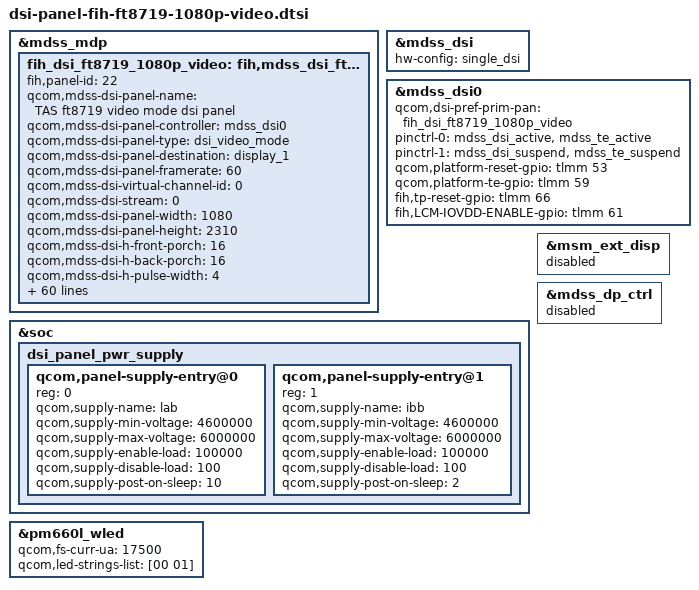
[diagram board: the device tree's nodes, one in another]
/* Copyright (c) 2013, The Linux Foundation. All rights reserved.
 *
 * This program is free software; you can redistribute it and/or modify
 * it under the terms of the GNU General Public License version 2 and
 * only version 2 as published by the Free Software Foundation.
 *
 * This program is distributed in the hope that it will be useful,
 * but WITHOUT ANY WARRANTY; without even the implied warranty of
 * MERCHANTABILITY or FITNESS FOR A PARTICULAR PURPOSE.  See the
 * GNU General Public License for more details.
 */

/*---------------------------------------------------------------------------
 * This file is autogenerated file using gcdb parser. Please do not edit it.
 * Update input XML file to add a new entry or update variable in this file
 * VERSION = "1.0"
 *---------------------------------------------------------------------------*/
&mdss_mdp {
	fih_dsi_ft8719_1080p_video: fih,mdss_dsi_ft8719_1080p_video {
		fih,panel-id = <22>;
		qcom,mdss-dsi-panel-name = "TAS ft8719 video mode dsi panel";
		qcom,mdss-dsi-panel-controller = <&mdss_dsi0>;
		qcom,mdss-dsi-panel-type = "dsi_video_mode";
		qcom,mdss-dsi-panel-destination = "display_1";
		qcom,mdss-dsi-panel-framerate = <60>;
		qcom,mdss-dsi-virtual-channel-id = <0>;
		qcom,mdss-dsi-stream = <0>;
		qcom,mdss-dsi-panel-width = <1080>;
		qcom,mdss-dsi-panel-height = <2310>;
		qcom,mdss-dsi-h-front-porch = <16>;
		qcom,mdss-dsi-h-back-porch = <16>;
		qcom,mdss-dsi-h-pulse-width = <4>;
		qcom,mdss-dsi-h-sync-skew = <0>;
		qcom,mdss-dsi-v-front-porch = <112>;
		qcom,mdss-dsi-v-back-porch = <12>;
		qcom,mdss-dsi-v-pulse-width = <4>;
		qcom,mdss-dsi-h-left-border = <0>;
		qcom,mdss-dsi-h-right-border = <0>;
		qcom,mdss-dsi-v-top-border = <0>;
		qcom,mdss-dsi-v-bottom-border = <0>;
		qcom,mdss-dsi-bpp = <24>;
		qcom,mdss-dsi-color-order = "rgb_swap_rgb";
		qcom,mdss-dsi-underflow-color = <0xff>;
		qcom,mdss-dsi-border-color = <0>;
		
		qcom,mdss-dsi-on-command = [
/*			39 01 00 00 00 00 02 00 00
			39 01 00 00 00 00 04 FF 87 19 01
			39 01 00 00 00 00 02 00 80
			39 01 00 00 00 00 03 FF 87 19
			39 01 00 00 00 00 02 00 A1
			39 01 00 00 00 00 06 B3 04 38 09 06 C0
			39 01 00 00 00 00 02 00 A6
			39 01 00 00 00 00 02 B3 F8
			39 01 00 00 00 00 02 00 CA
			39 01 00 00 00 00 02 C0 80
			39 01 00 00 00 00 02 00 E8
			39 01 00 00 00 00 02 C0 40
			39 01 00 00 00 00 02 00 85
			39 01 00 00 00 00 02 A7 03
			39 01 00 00 00 00 02 00 D0
			39 01 00 00 00 00 03 C3 36 6C
			39 01 00 00 00 00 02 00 D3
			39 01 00 00 00 00 02 C3 00
			39 01 00 00 00 00 02 00 D4
			39 01 00 00 00 00 03 C3 46 00
			39 01 00 00 00 00 02 00 D7
			39 01 00 00 00 00 02 C3 00
			39 01 00 00 00 00 02 00 E0
			39 01 00 00 00 00 09 C3 46 00 00 30 46 00 00 30
			39 01 00 00 00 00 02 00 80
			39 01 00 00 00 00 11 C2 81 00 01 8E 81 00 01 8F 82 00 01 8E 81 00 01 8F
			39 01 00 00 00 00 02 00 90
			39 01 00 00 00 00 11 C2 80 00 01 81 01 00 01 81 02 00 01 81 03 00 01 81
			39 01 00 00 00 00 02 00 A0
			39 01 00 00 00 00 10 C2 00 05 00 01 91 01 06 00 01 91 02 07 00 01 91
			39 01 00 00 00 00 02 00 B0
			39 01 00 00 00 00 10 C2 03 08 00 01 91 04 04 00 01 91 05 04 00 01 90
			39 01 00 00 00 00 02 00 C0
			39 01 00 00 00 00 10 C2 06 04 00 01 90 07 04 00 01 90 00 00 00 01 90
			39 01 00 00 00 00 02 00 D0
			39 01 00 00 00 00 10 C2 00 00 00 01 90 07 04 00 01 90 00 00 00 01 90
			39 01 00 00 00 00 02 00 E0
			39 01 00 00 00 00 09 C2 44 44 43 77 00 00 00 00
			39 01 00 00 00 00 02 00 80
			39 01 00 00 00 00 11 CB 01 FD 02 00 FD FD 00 02 00 00 FD 01 FC FC 00 CC
			39 01 00 00 00 00 02 00 90
			39 01 00 00 00 00 11 CB 00 00 00 00 00 00 00 00 00 00 00 FF 00 00 00 00
			39 01 00 00 00 00 02 00 A0
			39 01 00 00 00 00 05 CB 00 00 00 00
			39 01 00 00 00 00 02 00 B0
			39 01 00 00 00 00 05 CB D9 56 55 05
			39 01 00 00 00 00 02 00 80
			39 01 00 00 00 00 11 CC 00 00 00 00 00 00 00 02 22 00 00 0A 09 08 07 06
			39 01 00 00 00 00 02 00 90
			39 01 00 00 00 00 09 CC 29 04 1C 1D 1E 16 17 18
			39 01 00 00 00 00 02 00 80
			39 01 00 00 00 00 11 CD 00 00 00 00 00 00 00 02 22 00 00 0A 09 08 07 06
			39 01 00 00 00 00 02 00 90
			39 01 00 00 00 00 09 CD 29 04 1C 1D 1E 16 17 18
			39 01 00 00 00 00 02 00 A0
			39 01 00 00 00 00 11 CC 00 00 00 00 00 00 00 23 02 00 00 06 07 08 09 0A
			39 01 00 00 00 00 02 00 B0
			39 01 00 00 00 00 09 CC 29 04 1C 1D 1E 16 17 18
			39 01 00 00 00 00 02 00 A0
			39 01 00 00 00 00 11 CD 00 00 00 00 00 00 00 23 02 00 00 06 07 08 09 0A
			39 01 00 00 00 00 02 00 B0
			39 01 00 00 00 00 09 CD 29 04 1C 1D 1E 16 17 18
			39 01 00 00 00 00 02 00 86
			39 01 00 00 00 00 07 C0 01 00 00 01 1D 05
			39 01 00 00 00 00 02 00 96
			39 01 00 00 00 00 07 C0 01 00 00 01 1D 05
			39 01 00 00 00 00 02 00 A6
			39 01 00 00 00 00 07 C0 01 00 00 01 1D 05
			39 01 00 00 00 00 02 00 80
			39 01 00 00 00 00 07 C0 00 7C 00 6B 00 10
			39 01 00 00 00 00 02 00 A0
			39 01 00 00 00 00 07 C0 01 0B 00 3A 00 10
			39 01 00 00 00 00 02 00 B0
			39 01 00 00 00 00 06 C0 00 7C 02 02 10
			39 01 00 00 00 00 02 00 C1
			39 01 00 00 00 00 09 C0 00 B2 00 8D 00 77 00 D4
			39 01 00 00 00 00 02 00 D7
			39 01 00 00 00 00 07 C0 00 77 00 6E 00 10
			39 01 00 00 00 00 02 00 A5
			39 01 00 00 00 00 05 C1 00 29 00 02
			39 01 00 00 00 00 02 00 82
			39 01 00 00 00 00 0E CE 01 09 00 D7 00 D7 00 8F 00 8F 0D 0E 09
			39 01 00 00 00 00 02 00 90
			39 01 00 00 00 00 09 CE 00 82 0D 5C 00 82 80 09
			39 01 00 00 00 00 02 00 A0
			39 01 00 00 00 00 04 CE 10 00 00
			39 01 00 00 00 00 02 00 B0
			39 01 00 00 00 00 04 CE 22 00 00
			39 01 00 00 00 00 02 00 D1
			39 01 00 00 00 00 08 CE 00 0A 01 01 00 5C 01
			39 01 00 00 00 00 02 00 E1
			39 01 00 00 00 00 0C CE 08 02 15 02 15 02 15 00 2B 00 5F
			39 01 00 00 00 00 02 00 F1
			39 01 00 00 00 00 0A CE 16 0B 0F 00 D7 00 D9 00 E2
			39 01 00 00 00 00 02 00 B0
			39 01 00 00 00 00 05 CF 00 00 6B 6F
			39 01 00 00 00 00 02 00 B5
			39 01 00 00 00 00 05 CF 04 04 9E A2
			39 01 00 00 00 00 02 00 C0
			39 01 00 00 00 00 05 CF 08 08 B6 BA
			39 01 00 00 00 00 02 00 B5
			39 01 00 00 00 00 05 CF 00 00 08 0C
			39 01 00 00 00 00 02 00 90
			39 01 00 00 00 00 07 C0 00 7C 00 6B 00 10
			39 01 00 00 00 00 02 00 82
			39 01 00 00 00 00 02 CF 06
			39 01 00 00 00 00 02 00 84
			39 01 00 00 00 00 02 CF 06
			39 01 00 00 00 00 02 00 87
			39 01 00 00 00 00 02 CF 06
			39 01 00 00 00 00 02 00 89
			39 01 00 00 00 00 02 CF 06
			39 01 00 00 00 00 02 00 8A
			39 01 00 00 00 00 02 CF 07
			39 01 00 00 00 00 02 00 8B
			39 01 00 00 00 00 02 CF 00
			39 01 00 00 00 00 02 00 8C
			39 01 00 00 00 00 02 CF 06
			39 01 00 00 00 00 02 00 92
			39 01 00 00 00 00 02 CF 06
			39 01 00 00 00 00 02 00 94
			39 01 00 00 00 00 02 CF 06
			39 01 00 00 00 00 02 00 97
			39 01 00 00 00 00 02 CF 06
			39 01 00 00 00 00 02 00 99
			39 01 00 00 00 00 02 CF 06
			39 01 00 00 00 00 02 00 9A
			39 01 00 00 00 00 02 CF 07
			39 01 00 00 00 00 02 00 9B
			39 01 00 00 00 00 02 CF 00
			39 01 00 00 00 00 02 00 9C
			39 01 00 00 00 00 02 CF 06
			39 01 00 00 00 00 02 00 A0
			39 01 00 00 00 00 02 CF 24
			39 01 00 00 00 00 02 00 A2
			39 01 00 00 00 00 02 CF 06
			39 01 00 00 00 00 02 00 A4
			39 01 00 00 00 00 02 CF 06
			39 01 00 00 00 00 02 00 A7
			39 01 00 00 00 00 02 CF 06
			39 01 00 00 00 00 02 00 A9
			39 01 00 00 00 00 02 CF 06
			39 01 00 00 00 00 02 00 82
			39 01 00 00 00 00 03 C5 5A 5A
			39 01 00 00 00 00 02 00 84
			39 01 00 00 00 00 03 C5 28 28
			39 01 00 00 00 00 02 00 00
			39 01 00 00 00 00 29 E1 00 01 09 10 0F 1C 25 2D 38 F1 41 49 4F 55 89 5A 63 6B 72 57 7A 81 89 92 7E 9C A2 A9 B0 E2 B9 C3 D1 D9 62 E4 F2 FB FF D3
			39 01 00 00 00 00 02 00 00
			39 01 00 00 00 00 29 E2 00 01 09 10 0F 1E 27 2F 3A F1 43 4B 51 57 89 5C 65 6D 74 57 7C 83 8B 94 7E 9E A4 AB B2 E2 BB C5 D3 DB 62 E4 F2 FB FF D3
			39 01 00 00 00 00 02 00 00
			39 01 00 00 00 00 29 E3 00 01 09 10 0F 1C 25 2D 38 F1 41 49 4F 55 89 5A 63 6B 72 57 7A 81 89 92 7E 9C A2 A9 B0 E2 B9 C3 D1 D9 62 E4 F2 FB FF D3
			39 01 00 00 00 00 02 00 00
			39 01 00 00 00 00 29 E4 00 01 09 10 0F 1E 27 2F 3A F1 43 4B 51 57 89 5C 65 6D 74 57 7C 83 8B 94 7E 9E A4 AB B2 E2 BB C5 D3 DB 62 E4 F2 FB FF D3
			39 01 00 00 00 00 02 00 00
			39 01 00 00 00 00 29 E5 00 01 09 10 0F 1C 25 2D 38 F1 41 49 4F 55 89 5A 63 6B 72 57 7A 81 89 92 7E 9C A2 A9 B0 E2 B9 C3 D1 D9 62 E4 F2 FB FF D3
			39 01 00 00 00 00 02 00 00
			39 01 00 00 00 00 29 E6 00 01 09 10 0F 1E 27 2F 3A F1 43 4B 51 57 89 5C 65 6D 74 57 7C 83 8B 94 7E 9E A4 AB B2 E2 BB C5 D3 DB 62 E4 F2 FB FF D3
			39 01 00 00 00 00 02 00 00
			39 01 00 00 00 00 03 D8 2B 2B
			39 01 00 00 00 00 02 00 00
			39 01 00 00 00 00 04 D9 00 A0 A0
			39 01 00 00 00 00 02 00 A3
			39 01 00 00 00 00 02 C5 28
			39 01 00 00 00 00 02 00 A9
			39 01 00 00 00 00 02 C5 19
			39 01 00 00 00 00 02 00 85
			39 01 00 00 00 00 02 C4 1E
			39 01 00 00 00 00 02 00 8C
			39 01 00 00 00 00 04 C3 03 00 30
			39 01 00 00 00 00 02 00 86
			39 01 00 00 00 00 04 C5 00 60 0C
			39 01 00 00 00 00 02 00 83
			39 01 00 00 00 00 02 A4 23
			39 01 00 00 00 00 02 00 B0
			39 01 00 00 00 00 02 F5 00
			39 01 00 00 00 00 02 00 C1
			39 01 00 00 00 00 04 B6 09 89 68
			39 01 00 00 00 00 02 00 89
			39 01 00 00 00 00 02 F5 5A
			39 01 00 00 00 00 02 00 96
			39 01 00 00 00 00 02 F5 5A
			39 01 00 00 00 00 02 00 80
			39 01 00 00 00 00 02 A7 03
			39 01 00 00 00 00 02 00 B0
			39 01 00 00 00 00 03 F3 01 FE
			39 01 00 00 00 00 02 00 00
			39 01 00 00 00 00 04 FF FF FF FF*/
			05 01 00 00 78 00 02 11 00
			05 01 00 00 00 00 02 29 00
			05 01 00 00 0A 00 02 35 00
			39 01 00 00 00 00 03 51 FF 0F
			15 01 00 00 00 00 02 53 2C			
		];
		qcom,mdss-dsi-off-command = [
			05 01 00 00 0A 00 02 28 00
			05 01 00 00 96 00 02 10 00
		];
		qcom,suspend-ulps-enabled;
		qcom,mdss-dsi-on-command-state = "dsi_lp_mode";
		qcom,mdss-dsi-off-command-state = "dsi_hs_mode";
		qcom,mdss-dsi-h-sync-pulse = <0>;
		qcom,mdss-dsi-traffic-mode = "non_burst_sync_event";
		qcom,mdss-dsi-bllp-eof-power-mode;
		qcom,mdss-dsi-bllp-power-mode;
		qcom,mdss-dsi-lane-0-state;
		qcom,mdss-dsi-lane-1-state;
		qcom,mdss-dsi-lane-2-state;
		qcom,mdss-dsi-lane-3-state;
		qcom,mdss-dsi-t-clk-post = <0x0D>;
		qcom,mdss-dsi-t-clk-pre = <0x32>;
		/*Add by ZZDC sunqiupeng for esd check START*/
		//qcom,esd-check-enabled;
		qcom,mdss-dsi-panel-status-check-mode = "reg_read";
		qcom,mdss-dsi-panel-status-command = [06 01 00 01 00 00 01 0a
		06 01 00 01 00 00 01 0d
		06 01 00 01 00 00 01 ac];
		qcom,mdss-dsi-panel-status-command-state = "dsi_hs_mode";
		qcom,mdss-dsi-panel-status-value = <0x9c>,<0x00>,<0x00>;
		qcom,mdss-dsi-panel-on-check-value = <0x9c>,<0x00>,<0x00>;
		qcom,mdss-dsi-panel-status-read-length = <1>,<1>,<1>;
		qcom,mdss-dsi-panel-max-error-count = <3>;
		/*Add by ZZDC sunqiupeng for esd check END*/
		qcom,mdss-dsi-dma-trigger = "trigger_sw";
		qcom,mdss-dsi-mdp-trigger = "none";
		qcom,mdss-dsi-reset-sequence = <1 10>, <0 5>, <1 15>;

		qcom,mdss-pan-physical-width-dimension = <68>;
		qcom,mdss-pan-physical-height-dimension = <147>;
		qcom,mdss-pan-physical-width-dimension-full = <6885>;
		qcom,mdss-pan-physical-height-dimension-full = <14726>;
	};
};

&fih_dsi_ft8719_1080p_video {
	qcom,mdss-dsi-panel-timings-phy-v2 = [
		25 1F 09 0A 06 02 04 a0
		25 1F 09 0A 06 02 04 a0
		25 1F 09 0A 06 02 04 a0
		25 1F 09 0A 06 02 04 a0
		25 1F 09 0A 06 02 04 a0
	];
	qcom,mdss-dsi-bl-pmic-control-type = "bl_ctrl_wled";
	qcom,mdss-dsi-bl-min-level = <1>;
	qcom,mdss-dsi-bl-max-level = <4095>;
	qcom,panel-supply-entries = <&dsi_panel_pwr_supply>;
};

&mdss_dsi {
	hw-config = "single_dsi";
};

&mdss_dsi0 {
	qcom,dsi-pref-prim-pan = <&fih_dsi_ft8719_1080p_video>;
	pinctrl-names = "mdss_default", "mdss_sleep";
	pinctrl-0 = <&mdss_dsi_active &mdss_te_active>;
	pinctrl-1 = <&mdss_dsi_suspend &mdss_te_suspend>;
	qcom,platform-reset-gpio = <&tlmm 53 0>;
	qcom,platform-te-gpio = <&tlmm 59 0>;
	fih,tp-reset-gpio = <&tlmm 66 0>;
	fih,LCM-IOVDD-ENABLE-gpio = <&tlmm 61 0>;
};

&soc {
	/delete-node/dsi_panel_pwr_supply;

	dsi_panel_pwr_supply: dsi_panel_pwr_supply {
		#address-cells = <1>;
		#size-cells = <0>;

		qcom,panel-supply-entry@0 {
			reg = <0>;
			qcom,supply-name = "lab";
			qcom,supply-min-voltage = <4600000>;
			qcom,supply-max-voltage = <6000000>;
			qcom,supply-enable-load = <100000>;
			qcom,supply-disable-load = <100>;
			qcom,supply-post-on-sleep = <10>;
		};

		qcom,panel-supply-entry@1 {
			reg = <1>;
			qcom,supply-name = "ibb";
			qcom,supply-min-voltage = <4600000>;
			qcom,supply-max-voltage = <6000000>;
			qcom,supply-enable-load = <100000>;
			qcom,supply-disable-load = <100>;
			qcom,supply-post-on-sleep = <2>;
		};
	};
};

&msm_ext_disp {
	status = "disabled";
};

&mdss_dp_ctrl {
	status = "disabled";
};

&pm660l_wled {
	qcom,fs-curr-ua = <17500>;
	qcom,led-strings-list = [00 01];
};
